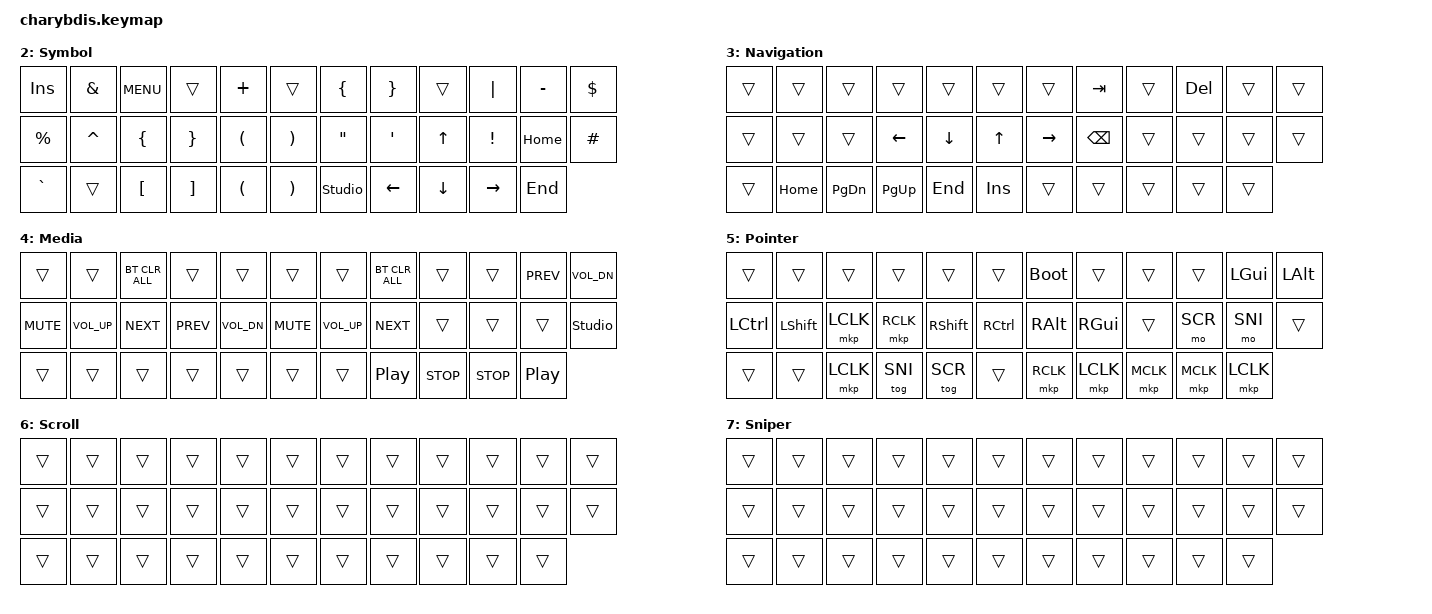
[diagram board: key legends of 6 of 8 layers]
#include <behaviors/mouse_keys.dtsi>
#include <dt-bindings/zmk/mouse.h>
#include <behaviors.dtsi>
#include <dt-bindings/zmk/bt.h>
#include <dt-bindings/zmk/ext_power.h>
#include <dt-bindings/zmk/keys.h>
#include <dt-bindings/zmk/pointing.h>
#include <dt-bindings/zmk/rgb.h>

#define BASE 0
#define NUFU 1
#define SYM 2
#define NAV 3
#define MED 4
#define POI 5
#define SCR 6
#define SNI 7

&sl { release-after-ms = <250>; };

&mt {
    tapping-term-ms = <200>;
    require-prior-idle-ms = <150>;
};

/ {
    #include "combos.dtsi"

    behaviors {
        hml: homewrow_mods_left {
            compatible = "zmk,behavior-hold-tap";
            label = "HOMEROW_MODS_LEFT_HAND";
            bindings = <&kp>, <&kp>;

            #binding-cells = <2>;
            tapping-term-ms = <280>;
            hold-trigger-key-positions = <5 6 7 8 9 15 16 17 18 19 25 26 27 28 29 33 34>;
            flavor = "balanced";
            quick-tap-ms = <175>;
            require-prior-idle-ms = <125>;
            hold-trigger-on-release;
        };

        hmr: homewrow_mods_right {
            compatible = "zmk,behavior-hold-tap";
            label = "HOMEROW_MODS_RIGHT_HAND";
            bindings = <&kp>, <&kp>;

            #binding-cells = <2>;
            tapping-term-ms = <280>;
            hold-trigger-key-positions = <0 1 2 3 4 10 11 12 13 14 20 21 22 23 24 30 31 32>;
            flavor = "balanced";
            quick-tap-ms = <175>;
            require-prior-idle-ms = <125>;
            hold-trigger-on-release;
        };
    };

    macros {
        ac: ac {
            compatible = "zmk,behavior-macro";
            #binding-cells = <0>;
            bindings = <&kp RC(A)>;
            label = "AC";
        };

        av: av {
            compatible = "zmk,behavior-macro";
            #binding-cells = <0>;
            bindings = <&kp LC(V)>;
            label = "AV";
        };

        pd: pd {
            compatible = "zmk,behavior-macro";
            #binding-cells = <0>;
            bindings = <&kp S &kp U &kp B &kp L &kp I &kp M &kp E &kp I &kp N &kp C &kp A &kp N &kp T &kp A &kp T &kp I &kp O &kp N &kp S>;
            label = "PD";
        };

        sa: sa {
            compatible = "zmk,behavior-macro";
            #binding-cells = <0>;
            bindings = <&kp S &kp E &kp L &kp E &kp C &kp T &kp SPACE &kp STAR &kp SPACE &kp F &kp R &kp O &kp M &kp SPACE>;
            label = "SA";
        };

        cf5: cf5 {
            compatible = "zmk,behavior-macro";
            #binding-cells = <0>;
            bindings = <&kp RC(F5)>;
            label = "CF5";
        };
    };

    keymap {
        compatible = "zmk,keymap";

        Base {
            label = "Base";
            bindings = <
&kp ESC         &kp N1   &kp N2  &kp N3    &kp N4        &kp N5           &kp N6                &kp N7       &kp N8     &kp N9   &kp N0       &kp BSPC
&kp TAB         &kp Q    &kp W   &kp F     &kp P         &kp B            &kp J                 &kp L        &kp U      &kp Y    &kp SQT      &kp RC(EQUAL)
&kp LEFT_SHIFT  &kp A    &kp R   &kp S     &kp T         &kp G            &kp M                 &kp N        &kp E      &kp I    &kp O        &kp RIGHT_SHIFT
&kp LCTRL       &lt 6 Z  &kp X   &kp C     &kp D         &kp V            &kp K                 &kp H        &kp COMMA  &kp DOT  &lt 3 SLASH  &kp RCTRL
                                 &kp SEMI  &lt 1 ENTER   &kp DELETE       &kp BACKSPACE         &lt 2 SPACE
                                           &kp LEFT_ALT  &kp BACKSLASH    &kp NON_US_BACKSLASH
            >;
        };

        NuFu {
            label = "Numeral/Function";
            bindings = <
&kp TILDE  &kp EXCLAMATION  &kp N7        &kp N8        &kp N9           &kp BACKSLASH        &kp CARET        &kp AMPERSAND  &kp ASTERISK  &kp LEFT_PARENTHESIS  &kp RIGHT_PARENTHESIS  &pd
&ac        &kp MINUS        &kp NUMBER_4  &kp N5        &kp NUMBER_6     &kp LBKT             &kp PAGE_UP      &kp F1         &kp F2        &kp F3                &kp F4                 &sa
&av        &trans           &kp NUMBER_1  &kp NUMBER_2  &kp NUMBER_3     &soft_off            &kp PAGE_DOWN    &kp F5         &kp F6        &kp F7                &kp F8                 &kp PAGE_UP
&trans     &trans           &trans        &kp N0        &kp EQUAL        &cf5                 &rgb_ug RGB_TOG  &kp F9         &kp F10       &kp F11               &kp F12                &kp PAGE_DOWN
                                          &kp LEFT_WIN  &kp RET          &ext_power EP_TOG    &kp BACKSPACE    &kp SPACE
                                                        &rgb_ug RGB_BRI  &rgb_ug RGB_BRD      &rgb_ug RGB_EFF
            >;
        };

        Symbol {
            label = "Symbol";
            bindings = <
&kp INSERT  &kp AMPS   &kp C_MENU      &trans           &kp PLUS              &trans                   &kp LBRC        &kp RBRC  &trans          &kp PIPE   &kp MINUS  &kp DLLR
&kp PRCNT   &kp CARET  &kp LEFT_BRACE  &kp RIGHT_BRACE  &kp LPAR              &kp RPAR                 &kp DQT         &kp APOS  &kp UP_ARROW    &kp EXCL   &kp HOME   &kp HASH
&kp GRAVE   &trans     &kp LBKT        &kp RBKT         &kp LEFT_PARENTHESIS  &kp RIGHT_PARENTHESIS    &studio_unlock  &kp LEFT  &kp DOWN_ARROW  &kp RIGHT  &kp END
            >;
        };

        Navigation {
            label = "Navigation";
            bindings = <
&trans  &trans    &trans         &trans       &trans    &trans     &trans     &kp TAB        &trans  &kp DELETE  &trans  &trans
&trans  &trans    &trans         &kp LEFT     &kp DOWN  &kp UP     &kp RIGHT  &kp BACKSPACE  &trans  &trans      &trans  &trans
&trans  &kp HOME  &kp PAGE_DOWN  &kp PAGE_UP  &kp END   &kp INS    &trans     &trans         &trans  &trans      &trans
            >;
        };

        Media {
            label = "Media";
            bindings = <
&trans      &trans        &bt BT_CLR_ALL  &trans      &trans        &trans        &trans        &bt BT_CLR_ALL    &trans      &trans      &kp C_PREV        &kp C_VOL_DN
&kp C_MUTE  &kp C_VOL_UP  &kp C_NEXT      &kp C_PREV  &kp C_VOL_DN  &kp C_MUTE    &kp C_VOL_UP  &kp C_NEXT        &trans      &trans      &trans            &studio_unlock
&trans      &trans        &trans          &trans      &trans        &trans        &trans        &kp C_PLAY_PAUSE  &kp C_STOP  &kp C_STOP  &kp C_PLAY_PAUSE
            >;
        };

        Pointer {
            label = "Pointer";
            bindings = <
&trans     &trans     &trans     &trans     &trans     &trans       &bootloader  &trans     &trans     &trans     &kp LGUI   &kp LALT
&kp LCTRL  &kp LSHFT  &mkp LCLK  &mkp RCLK  &kp RSHFT  &kp RCTRL    &kp RALT     &kp RGUI   &trans     &mo SCR    &mo SNI    &trans
&trans     &trans     &mkp LCLK  &tog SNI   &tog SCR   &trans       &mkp RCLK    &mkp LCLK  &mkp MCLK  &mkp MCLK  &mkp LCLK
            >;
        };

        Scroll {
            label = "Scroll";
            bindings = <
&trans  &trans  &trans  &trans  &trans  &trans    &trans  &trans  &trans  &trans  &trans  &trans
&trans  &trans  &trans  &trans  &trans  &trans    &trans  &trans  &trans  &trans  &trans  &trans
&trans  &trans  &trans  &trans  &trans  &trans    &trans  &trans  &trans  &trans  &trans
            >;
        };

        Sniper {
            label = "Sniper";
            bindings = <
&trans  &trans  &trans  &trans  &trans  &trans    &trans  &trans  &trans  &trans  &trans  &trans
&trans  &trans  &trans  &trans  &trans  &trans    &trans  &trans  &trans  &trans  &trans  &trans
&trans  &trans  &trans  &trans  &trans  &trans    &trans  &trans  &trans  &trans  &trans
            >;
        };
    };
};
